# PIC32MZ1025W104132 register map
Vendor: Microchip
Registers are 32-bit, read-write, no defined reset value unless marked. A register's access mark holds for its fields unless they carry their own. Addresses are absolute, and some are shared; only a register's first bit layout is shown; [hi:lo] are bit positions; {n}, {i} and the like mark numbered series.

## NVM
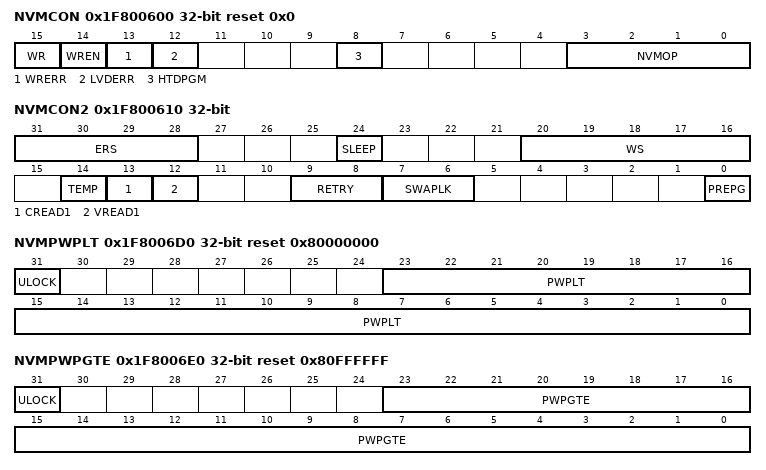
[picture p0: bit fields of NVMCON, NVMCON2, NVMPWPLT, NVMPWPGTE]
0x1F800600 NVMCON reset 0x0
  [15] WR, [14] WREN, [13] WRERR, [12] LVDERR, [8] HTDPGM, [3:0] NVMOP
0x1F800610 NVMCON2 — (power-on value 0000-------11111-x00--0000-----0)
  [31:28] ERS, [24] SLEEP, [20:16] WS, [14] TEMP, [13] CREAD1, [12] VREAD1, [9:8] RETRY, [7:6] SWAPLK, [0] PREPG
0x1F800620 NVMKEY wo reset 0x0
0x1F800630 NVMADDR reset 0x0
{0x1F800640+0x10*i} NVMDATA{i} reset 0x0 (i=0..7)
0x1F8006C0 NVMSRCADDR reset 0x0
0x1F8006D0 NVMPWPLT reset 0x80000000
  [31] ULOCK ro, [23:0] PWPLT
0x1F8006E0 NVMPWPGTE reset 0x80FFFFFF
  [31] ULOCK ro, [23:0] PWPGTE
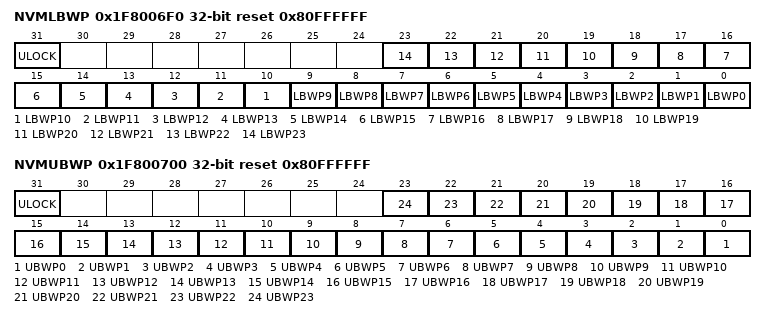
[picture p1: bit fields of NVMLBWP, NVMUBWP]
0x1F8006F0 NVMLBWP reset 0x80FFFFFF
  [31] ULOCK ro, [n] LBWP{n} (n=0..23)
0x1F800700 NVMUBWP reset 0x80FFFFFF
  [31] ULOCK ro, [n] UBWP{n} (n=0..23)

## WDT
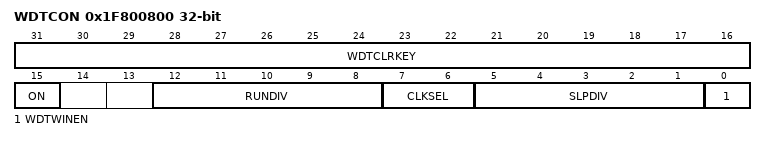
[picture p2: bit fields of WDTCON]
0x1F800800 WDTCON — (power-on value 0000000000000000x--xxxxxxxxxxxx0)
  [31:16] WDTCLRKEY wo, [15] ON, [12:8] RUNDIV ro, [7:6] CLKSEL ro, [5:1] SLPDIV ro, [0] WDTWINEN

## DMT
0x1F800A00 DMTCON reset 0x0
  [15] ON
0x1F800A10 DMTPRECLR reset 0x0
  [15:8] STEP1
0x1F800A20 DMTCLR reset 0x0
  [7:0] STEP2
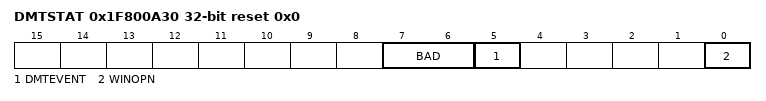
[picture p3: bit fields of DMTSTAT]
0x1F800A30 DMTSTAT ro reset 0x0
  [7:6] BAD, [5] DMTEVENT, [0] WINOPN
0x1F800A40 DMTCNT ro reset 0x0
  [31:0] COUNTER
0x1F800A50 DMTHOLDREG ro reset 0x0
  [15:0] UPRCNT
0x1F800A60 DMTPSCNT ro — (power-on value xxxxxxxxxxxxxxxxxxxxxxxxxxxxxxxx)
  [31:0] PSCNT
0x1F800A70 DMTPSINTV ro — (power-on value xxxxxxxxxxxxxxxxxxxxxxxxxxxxxxxx)
  [31:0] PSINTV

## CRU
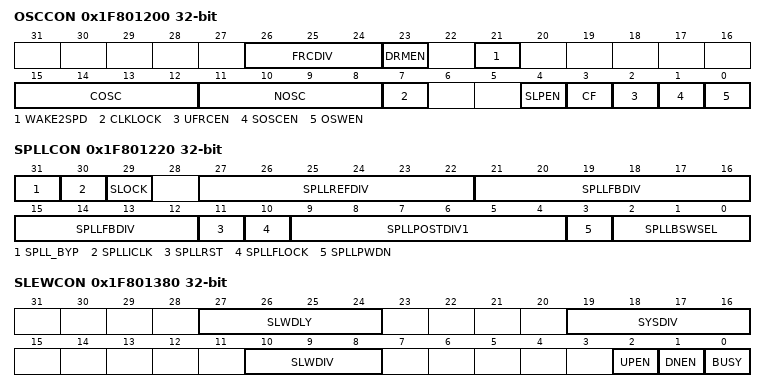
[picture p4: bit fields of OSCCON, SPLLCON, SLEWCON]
0x1F801200 OSCCON — (power-on value -----0000-x-----0000xxxx0--000x0)
  [26:24] FRCDIV, [23] DRMEN, [21] WAKE2SPD, [15:12] COSC ro, [11:8] NOSC, [7] CLKLOCK, [4] SLPEN, [3] CF, [2] UFRCEN, [1] SOSCEN, [0] OSWEN
0x1F801210 OSCTUN reset 0x0
  [5:0] TUN
0x1F801220 SPLLCON — (power-on value xxx-xxxxxxxxxxxxxxxxxxxxxxxxxxxx)
  [31] SPLL_BYP, [30] SPLLICLK, [29] SLOCK, [27:22] SPLLREFDIV, [21:12] SPLLFBDIV, [11] SPLLRST, [10] SPLLFLOCK, [9:4] SPLLPOSTDIV1, [3] SPLLPWDN, [2:0] SPLLBSWSEL
0x1F801380 SLEWCON — (power-on value ----xxxx----0000-----000-----000)
  [27:24] SLWDLY, [19:16] SYSDIV, [10:8] SLWDIV, [2] UPEN, [1] DNEN, [0] BUSY

## UART3
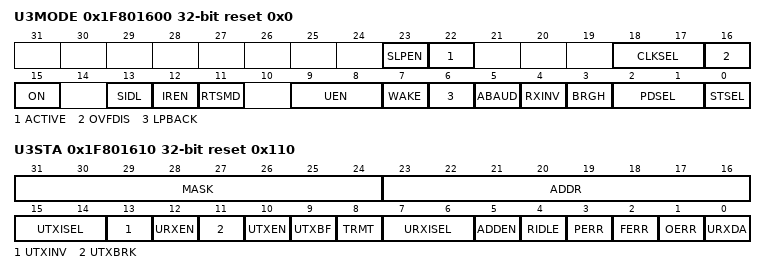
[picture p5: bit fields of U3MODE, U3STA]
0x1F801600 U3MODE reset 0x0
  [23] SLPEN, [22] ACTIVE, [18:17] CLKSEL, [16] OVFDIS, [15] ON, [13] SIDL, [12] IREN, [11] RTSMD, [9:8] UEN, [7] WAKE, [6] LPBACK, [5] ABAUD, [4] RXINV, [3] BRGH, [2:1] PDSEL, [0] STSEL
0x1F801610 U3STA reset 0x110
  [31:24] MASK
  [23:16] ADDR
  [15:14] UTXISEL
  [13] UTXINV
  [12] URXEN
  [11] UTXBRK
  [10] UTXEN
  [9] UTXBF ro
  [8] TRMT ro
  [7:6] URXISEL
  [5] ADDEN
  [4] RIDLE ro
  [3] PERR ro
  [2] FERR ro
  [1] OERR — (can only be cleared)
  [0] URXDA ro
0x1F801620 U3TXREG reset 0x0
  [8:0] U3TXREG
0x1F801630 U3RXREG ro reset 0x0
  [8:0] U3RXREG
0x1F801640 U3BRG reset 0x0
  [19:0] BRG

## PTG
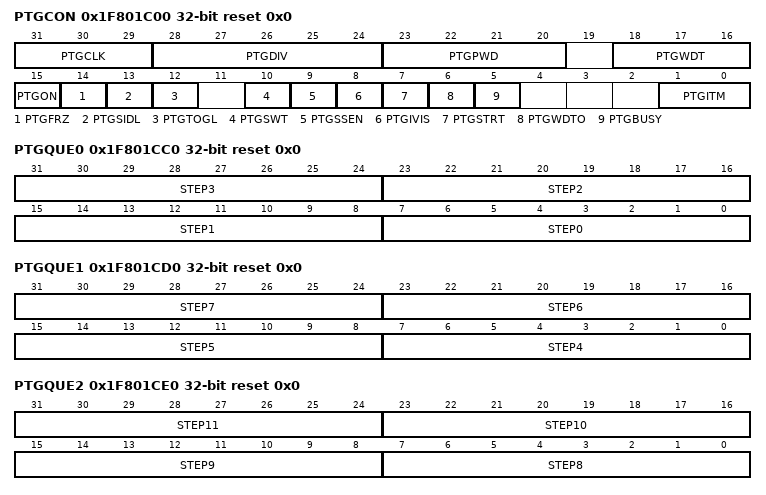
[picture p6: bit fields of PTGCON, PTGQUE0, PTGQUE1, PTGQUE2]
0x1F801C00 PTGCON reset 0x0
  [31:29] PTGCLK, [28:24] PTGDIV, [23:20] PTGPWD, [18:16] PTGWDT, [15] PTGON, [14] PTGFRZ, [13] PTGSIDL, [12] PTGTOGL, [10] PTGSWT, [9] PTGSSEN, [8] PTGIVIS, [7] PTGSTRT, [6] PTGWDTO ro, [5] PTGBUSY ro, [1:0] PTGITM
0x1F801C10 PTGBTE reset 0x0
0x1F801C20 PTGHOLD reset 0x0
  [15:0] PTGHOLD
0x1F801C30 PTGT0LIM reset 0x0
  [15:0] PTGT0LIM
0x1F801C40 PTGT1LIM reset 0x0
  [15:0] PTGT1LIM
0x1F801C50 PTGSDLIM reset 0x0
  [15:0] PTGSDLIM
0x1F801C60 PTGC0LIM reset 0x0
  [15:0] PTGC0LIM
0x1F801C70 PTGC1LIM reset 0x0
  [15:0] PTGC1LIM
0x1F801C80 PTGADJ reset 0x0
  [15:0] PTGADJ
0x1F801C90 PTGL0 reset 0x0
  [15:0] PTGL0
0x1F801CA0 PTGQPTR reset 0x0
  [4:0] PTGQPTR
0x1F801CC0 PTGQUE0 reset 0x0
  [8n+7:8n] STEP{n} (n=0..3)
0x1F801CD0 PTGQUE1 reset 0x0
  [8n-25:8n-32] STEP{n} (n=4..7)
0x1F801CE0 PTGQUE2 reset 0x0
  [8n-57:8n-64] STEP{n} (n=8..11)
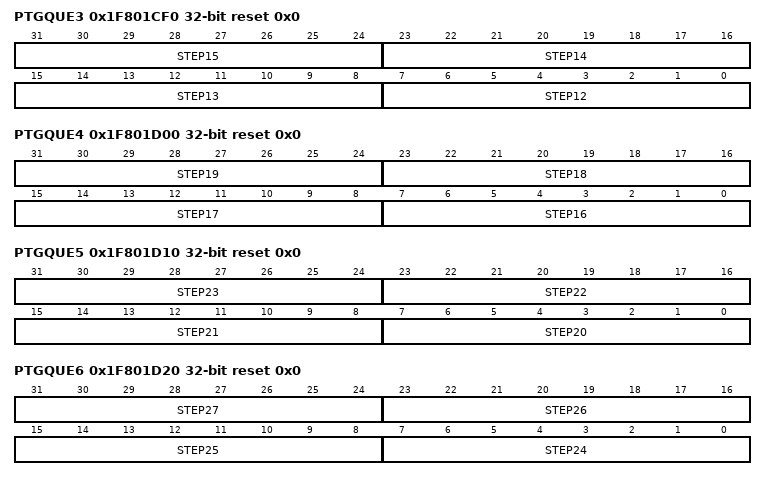
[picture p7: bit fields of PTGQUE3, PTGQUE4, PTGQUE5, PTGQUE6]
0x1F801CF0 PTGQUE3 reset 0x0
  [8n-89:8n-96] STEP{n} (n=12..15)
0x1F801D00 PTGQUE4 reset 0x0
  [8n-121:8n-128] STEP{n} (n=16..19)
0x1F801D10 PTGQUE5 reset 0x0
  [8n-153:8n-160] STEP{n} (n=20..23)
0x1F801D20 PTGQUE6 reset 0x0
  [8n-185:8n-192] STEP{n} (n=24..27)
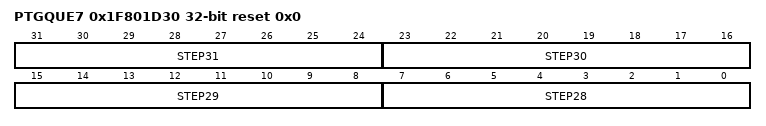
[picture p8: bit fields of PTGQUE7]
0x1F801D30 PTGQUE7 reset 0x0
  [8n-217:8n-224] STEP{n} (n=28..31)
